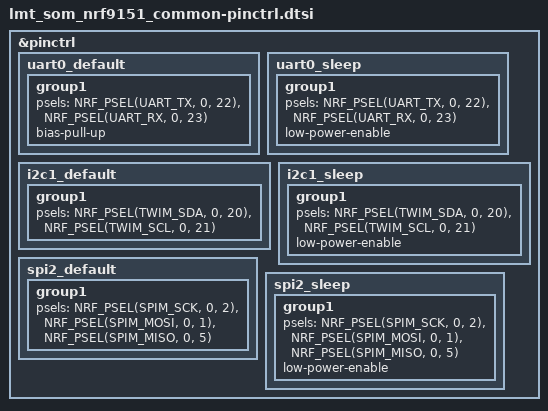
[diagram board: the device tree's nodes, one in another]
/*
 * Copyright (c) 2025 Latvijas Mobilais Telefons
 * SPDX-License-Identifier: Apache-2.0
 */

&pinctrl {
	uart0_default: uart0_default {
		group1 {
			psels = <NRF_PSEL(UART_TX, 0, 22)>,
				<NRF_PSEL(UART_RX, 0, 23)>;
			bias-pull-up;
		};
	};

	uart0_sleep: uart0_sleep {
		group1 {
			psels = <NRF_PSEL(UART_TX, 0, 22)>,
				<NRF_PSEL(UART_RX, 0, 23)>;
			low-power-enable;
		};
	};

	i2c1_default: i2c1_default {
		group1 {
			psels = <NRF_PSEL(TWIM_SDA, 0, 20)>,
				<NRF_PSEL(TWIM_SCL, 0, 21)>;
		};
	};

	i2c1_sleep: i2c1_sleep {
		group1 {
			psels = <NRF_PSEL(TWIM_SDA, 0, 20)>,
				<NRF_PSEL(TWIM_SCL, 0, 21)>;
			low-power-enable;
		};
	};

	spi2_default: spi2_default {
		group1 {
			psels = <NRF_PSEL(SPIM_SCK, 0, 2)>,
				<NRF_PSEL(SPIM_MOSI, 0, 1)>,
				<NRF_PSEL(SPIM_MISO, 0, 5)>;
		};
	};

	spi2_sleep: spi2_sleep {
		group1 {
			psels = <NRF_PSEL(SPIM_SCK, 0, 2)>,
				<NRF_PSEL(SPIM_MOSI, 0, 1)>,
				<NRF_PSEL(SPIM_MISO, 0, 5)>;
			low-power-enable;
		};
	};

};
